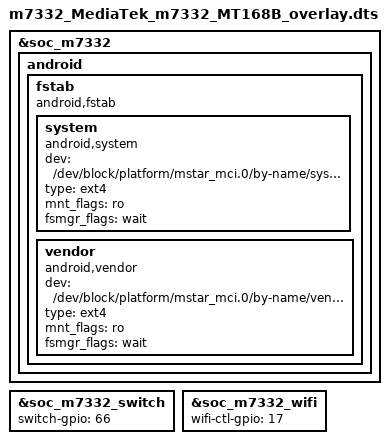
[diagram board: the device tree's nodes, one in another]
/dts-v1/;
/plugin/;

/ {
	fragment@0 {
		target = <&soc_m7332>;
		__overlay__ {
			android {
				fstab {
					compatible = "android,fstab";
					system {
						compatible = "android,system";
						dev = "/dev/block/platform/mstar_mci.0/by-name/system";
						type = "ext4";
						mnt_flags = "ro";
						fsmgr_flags = "wait";
					};
					vendor {
						compatible = "android,vendor";
						dev = "/dev/block/platform/mstar_mci.0/by-name/vendor";
						type = "ext4";
						mnt_flags = "ro";
						fsmgr_flags = "wait";
					};
				};
			};
		};
	};

	fragment@1 {
		target = <&soc_m7332_switch>;
		__overlay__ {
			switch-gpio = <66>;
		};
	};

	fragment@2 {
		target = <&soc_m7332_wifi>;
		__overlay__ {
			wifi-ctl-gpio = <17>;
		};
	};
};


